# SN32F760B register map
Vendor: SONiX Technology Co., Ltd.; Series: SN32F760B; File version: 1.3
CPU: CM0 r0p0, little endian, no MPU, no FPU, 2 interrupt priority bits
Registers are 32-bit, read-write, reset 0x0 unless marked. A register's access mark holds for its fields unless they carry their own. Offsets are from the block's base; [hi:lo] are bit positions; {n}, {i} and the like mark numbered series.

## SN_WDT — Watchdog Timer
Base 0x40010000
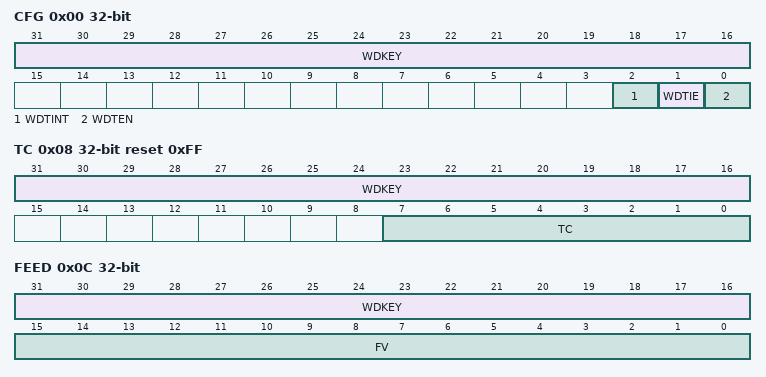
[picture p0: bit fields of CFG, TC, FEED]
0x00 CFG — Offset:0x00 WDT Configuration Register
  [31:16] WDKEY wo — WDT register key
  [2] WDTINT — WDT interrupt flag
    0=No (No WDT time-out); 1=WDT time-out (WDT interrupt is triggered if WDTIE=1)
  [1] WDTIE — WDT interrupt enable
    0=Disable (WDT reset when WDT time-out); 1=Enable WDT interrupt
  [0] WDTEN — WDT enable
    0=Disable WDT; 1=Enable WDT
0x08 TC reset 0xFF — Offset:0x08 WDT Timer Constant Register
  [31:16] WDKEY wo — WDT register key
  [7:0] TC — Watchdog timer constant reload value
0x0C FEED wo — Offset:0x0C WDT Feed Register
  [31:16] WDKEY — WDT register key
  [15:0] FV — Watchdog feed value

## SN_I2C0 — I2C0
Base 0x40018000
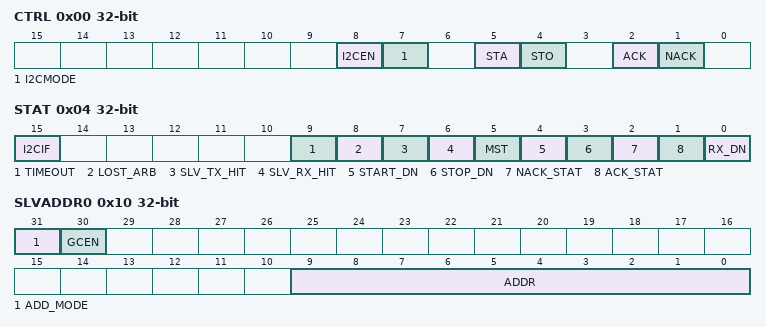
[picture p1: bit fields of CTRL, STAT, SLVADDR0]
0x00 CTRL — Offset:0x00 I2Cn Control Register
  [8] I2CEN — I2Cn interface enable
    0=Disable I2C; 1=Enable I2C
  [7] I2CMODE
    0=Standard/Fast mode
  [5] STA — START assert flag
    0=No action (No START condition or Repeated START condition will be generated); 1=Assert (Enter master mode and transmit a START or Repeated START condition)
  [4] STO — STOP assert flag
    0=Idle (STOP condition idle); 1=Assert (Transmit a STOP condition in master mode, or recover from an error condition in slave mode)
  [2] ACK — ACK assert flag
    0=No (Master: No action/Slave: Assert NACK after receiving); 1=Assert ACK during the acknowledge clock pulse on SCLn
  [1] NACK — NACK assert flag
    0=No action; 1=Assert NACK during the acknowledge clock pulse on SCLn
0x04 STAT — Offset:0x04 I2Cn Status Register
  [15] I2CIF — I2C interrupt flag
    0=I2C status doesn't change; 1=I2C status changes
  [9] TIMEOUT ro — Time-out status
    0=No timeout; 1=Timeout
  [8] LOST_ARB ro — Lost arbitration status
    0=Not lost arbitration; 1=Lost arbitration
  [7] SLV_TX_HIT ro — Slave TX address hit flag
    0=No matched slave address; 1=Slave address hit, and is called for TX
  [6] SLV_RX_HIT ro — Slave RX address hit flag
    0=No matched slave address; 1=Slave address hit, and is called for RX
  [5] MST ro — I2C master/slave status
    0=Slave (Act as Slave); 1=Master (Act as Master)
  [4] START_DN ro — START done status
    0=No (No START condition); 1=Assert (Transmit or receive a START condition)
  [3] STOP_DN ro — STOP done status
    0=No (No STOP condition); 1=Done (Transmit or receive a STOP condition)
  [2] NACK_STAT ro — NACK done status
    0=No (No NACK received); 1=Done (Receive a NACK)
  [1] ACK_STAT ro — ACK done status
    0=No (No ACK received); 1=Done (Receive an ACK)
  [0] RX_DN ro — RX done status
    0=Not done (No RX with ACK/NACK transfer); 1=Done (8-bit RX with ACK/NACK transfer)
0x08 TXDATA — Offset:0x08 I2Cn TX Data Register
  [7:0] Data — TX Data
0x0C RXDATA ro — Offset:0x0C I2Cn RX Data Register
  [7:0] Data — RX Data received when RX_DN=1
0x10 SLVADDR0 — Offset:0x10 I2Cn Slave Address 0 Register
  [31] ADD_MODE — Slave address mode
    0=7-bit slave address mode; 1=10-bit slave address mode
  [30] GCEN — General call address enable
    0=Disable general call address; 1=Enable general call address (0x0)
  [9:0] ADDR — I2Cn slave address 0
{0x10+4i} SLVADDR{i} (i=1..3) — Offset:{0x10+4i} I2Cn Slave Address {i} Register
  [9:0] ADDR — I2Cn slave address {i}
0x20 SCLHT reset 0x4 — Offset:0x20 I2Cn SCL High Time Register
  [7:0] SCLH — SCLn High period time=(SCLHT+1)*I2Cn_PCLK cycle
0x24 SCLLT reset 0x4 — Offset:0x24 I2Cn SCL Low Time Register
  [7:0] SCLL — SCLn Low period time=(SCLLT+1)*I2Cn_PCLK cycle
0x2C TOCTRL — Offset:0x2C I2Cn Timeout Control Register
  [15:0] TO — Timeout period time = TO*I2Cn_PCLK cycle

## SN_FLASH — FLASH Memory Control Registers
Base 0x40062000
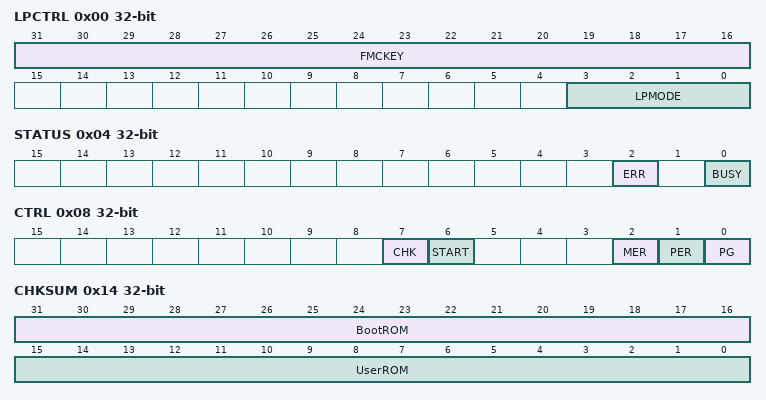
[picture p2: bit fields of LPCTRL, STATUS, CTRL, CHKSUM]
0x00 LPCTRL — Offset:0x00 Flash Low Power Control Register
  [31:16] FMCKEY wo — FMC verify key
  [3:0] LPMODE — Flash Low Power mode selection bit
    0=0000b (HCLK is less than or equal to 12MHz); 2=0010b (HCLK is less than or equal to 8KHz); 3=0011b (HCLK is more than 12MHz, and less than or equal to 24MHz); 5=0101b (HCLK is more than 24MHz)
0x04 STATUS — Offset:0x04 Flash Status Register
  [2] ERR — Erase/Error flag
    0=No error; 1=Error (The address is illegal or over page boundary)
  [0] BUSY ro — Busy flag
    0=Idle (FMC is idle); 1=Busy (Flash operation is in process)
0x08 CTRL — Offset:0x08 Flash Control Register
  [7] CHK — Checksum calculation chosen
    0=Disable; 1=Enable (Trigger checksum calculation)
  [6] START — Start erase/program operation
    0=Stop/finish operation; 1=Start erase/program operation
  [2] MER — Mass erase mode chosen bit
    0=Disable masse erase mode; 1=Enable mass erase mode
  [1] PER — Page erase mode chosen bit
    0=Disable page erase mode; 1=Enable page erase mode
  [0] PG — Flash program mode chosen bit
    0=Disable Flash program mode; 1=Enable Flash program mode
0x0C DATA — Offset:0x0C Flash Data Register
0x10 ADDR — Offset:0x10 Flash Address Register
0x14 CHKSUM ro — Offset:0x14 Flash Checksum Register
  [31:16] BootROM — Checksum of Boot ROM
  [15:0] UserROM — Checksum of User ROM

## SN_UC — UC Registers
Base 0x1FFF2228
0x00 L4BYTE ro — Offset:0x00 UC Low 4 Byte Register
0x04 H4BYTE ro — Offset:0x04 UC High 4 Byte Register

## Notices in the file
Copyright (C) 2019 ARM Limited. All rights reserved.
